# SERDES_10G0 register map
Vendor: Texas Instruments
Peripheral module from a debugger description file (folder J7VCL).
Registers are 32-bit, access per field, reset 0x0 unless marked. A register's access mark holds for its fields unless they carry their own. Offsets are as the file gives them; lines under a group give offsets from that group; [hi:lo] are bit positions; {n}, {i} and the like mark numbered series; 'fields as' and 'values as' point back to an identical list; <NAME> marks a mode.

## SERDES_10G0 (part 1 of 8)
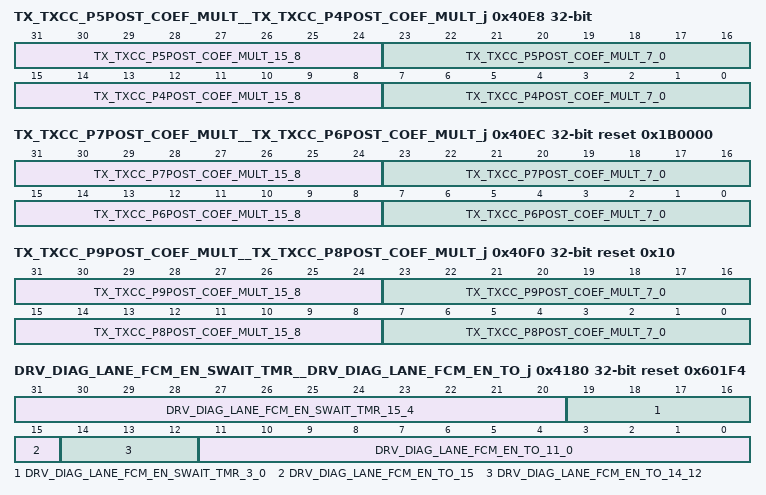
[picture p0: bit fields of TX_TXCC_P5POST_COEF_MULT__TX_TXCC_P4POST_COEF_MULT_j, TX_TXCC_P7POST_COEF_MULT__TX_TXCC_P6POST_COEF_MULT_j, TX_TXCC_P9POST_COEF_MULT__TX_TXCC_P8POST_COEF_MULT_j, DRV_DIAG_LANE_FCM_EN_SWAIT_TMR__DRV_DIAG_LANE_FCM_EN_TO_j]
0x40E8 TX_TXCC_P5POST_COEF_MULT__TX_TXCC_P4POST_COEF_MULT_j — Preset 4 post emphasis coefficient multiplier value register Offset = 40E8h + (j * 400h); where j = 0h to 3h
  [31:24] TX_TXCC_P5POST_COEF_MULT_15_8 ro — Reserved
  [23:16] TX_TXCC_P5POST_COEF_MULT_7_0 rw — Preset 5 post emphasis coefficient multiplier value : The value in this field specifies the multiplier value used to generate the preset 5 post emphasis coefficient value from the FS value.
  [15:8] TX_TXCC_P4POST_COEF_MULT_15_8 ro — Reserved
  [7:0] TX_TXCC_P4POST_COEF_MULT_7_0 rw — Preset 4 post emphasis coefficient multiplier value : The value in this field specifies the multiplier value used to generate the preset 4 post emphasis coefficient value from the FS value.
0x40EC TX_TXCC_P7POST_COEF_MULT__TX_TXCC_P6POST_COEF_MULT_j reset 0x1B0000 — Preset 6 post emphasis coefficient multiplier value register Offset = 40ECh + (j * 400h); where j = 0h to 3h
  [31:24] TX_TXCC_P7POST_COEF_MULT_15_8 ro — Reserved
  [23:16] TX_TXCC_P7POST_COEF_MULT_7_0 rw — Preset 7 post emphasis coefficient multiplier value : The value in this field specifies the multiplier value used to generate the preset 7 post emphasis coefficient value from the FS value.
  [15:8] TX_TXCC_P6POST_COEF_MULT_15_8 ro — Reserved
  [7:0] TX_TXCC_P6POST_COEF_MULT_7_0 rw — Preset 6 post emphasis coefficient multiplier value : The value in this field specifies the multiplier value used to generate the preset 6 post emphasis coefficient value from the FS value.
0x40F0 TX_TXCC_P9POST_COEF_MULT__TX_TXCC_P8POST_COEF_MULT_j reset 0x10 — Preset 8 post emphasis coefficient multiplier value register Offset = 40F0h + (j * 400h); where j = 0h to 3h
  [31:24] TX_TXCC_P9POST_COEF_MULT_15_8 ro — Reserved
  [23:16] TX_TXCC_P9POST_COEF_MULT_7_0 rw — Preset 9 post emphasis coefficient multiplier value : The value in this field specifies the multiplier value used to generate the preset 9 post emphasis coefficient value from the FS value.
  [15:8] TX_TXCC_P8POST_COEF_MULT_15_8 ro — Reserved
  [7:0] TX_TXCC_P8POST_COEF_MULT_7_0 rw — Preset 8 post emphasis coefficient multiplier value : The value in this field specifies the multiplier value used to generate the preset 8 post emphasis coefficient value from the FS value.
0x4180 DRV_DIAG_LANE_FCM_EN_SWAIT_TMR__DRV_DIAG_LANE_FCM_EN_TO_j reset 0x601F4 — Lane fast common mode enable timeout register Offset = 4180h + (j * 400h); where j = 0h to 3h
  [31:20] DRV_DIAG_LANE_FCM_EN_SWAIT_TMR_15_4 ro — Reserved
  [19:16] DRV_DIAG_LANE_FCM_EN_SWAIT_TMR_3_0 rw — Lane fast common mode enable sample wait timer value: This specifies the number of reference clock cycles the fast establishment of common mode process will wait between changing the state of the signals controlling the analog common mode sense circuits, and testing the results of the new state.
  [15] DRV_DIAG_LANE_FCM_EN_TO_15 rw — Bypass fast establishment of common mode enable: When enabled, the fast establishment of common mode function will be bypassed.
  [14:12] DRV_DIAG_LANE_FCM_EN_TO_14_12 ro — Reserved
  [11:0] DRV_DIAG_LANE_FCM_EN_TO_11_0 rw — Lane fast common mode enable timeout value: The usage of the value of this field is a function of the state of the bypass fast establishment of common mode enable bit in this register.
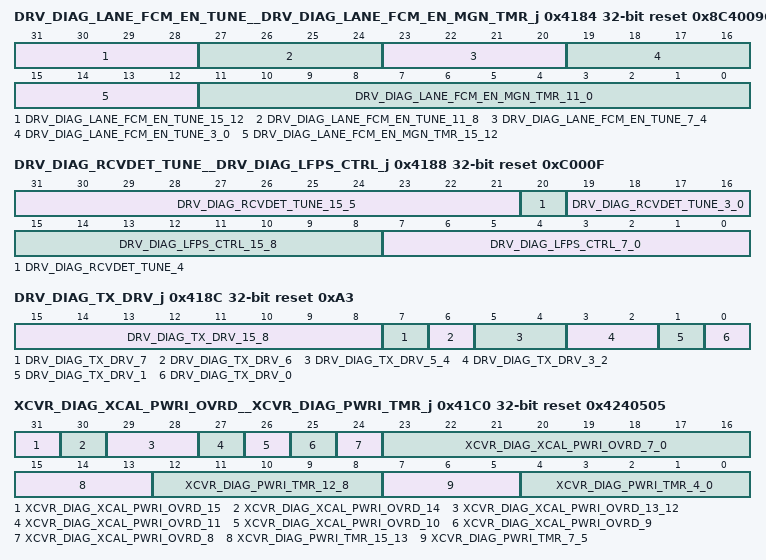
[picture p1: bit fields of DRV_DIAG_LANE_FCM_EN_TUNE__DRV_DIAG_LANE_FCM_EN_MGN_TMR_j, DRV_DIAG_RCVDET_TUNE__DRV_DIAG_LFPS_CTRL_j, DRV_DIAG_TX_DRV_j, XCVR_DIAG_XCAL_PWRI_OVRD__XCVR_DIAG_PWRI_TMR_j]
0x4184 DRV_DIAG_LANE_FCM_EN_TUNE__DRV_DIAG_LANE_FCM_EN_MGN_TMR_j reset 0x8C40096 — Lane fast common mode enable margin timer register Offset = 4184h + (j * 400h); where j = 0h to 3h
  [31:28] DRV_DIAG_LANE_FCM_EN_TUNE_15_12 ro — Reserved
  [27:24] DRV_DIAG_LANE_FCM_EN_TUNE_11_8 rw — Common mode sense reference DAC voltage initial test: This field sets the common mode detect reference voltage for the common mode detect comparator, when the fast establishment of common mode function is checking the initial state of the txda_cm_sense_comp_out signal.
  [23:20] DRV_DIAG_LANE_FCM_EN_TUNE_7_4 rw — Common mode sense reference DAC voltage high test: This field sets the common mode detect reference voltage for the common mode detect comparator, when the fast establishment of common mode function is waiting for the txda_cm_sense_comp_out signal from the analog to be driven high.
  [19:16] DRV_DIAG_LANE_FCM_EN_TUNE_3_0 rw — Common mode sense reference DAC voltage low test: This field sets the common mode detect reference voltage for the common mode detect comparator, when the fast establishment of common mode function is waiting for the txda_cm_sense_comp_out signal from the analog to be driven low.
  [15:12] DRV_DIAG_LANE_FCM_EN_MGN_TMR_15_12 ro — Reserved
  [11:0] DRV_DIAG_LANE_FCM_EN_MGN_TMR_11_0 rw — Lane fast common mode enable margin timer value: This specifies the number of reference clock cycles the fast establishment of common mode process will enable all the margin segments for.
0x4188 DRV_DIAG_RCVDET_TUNE__DRV_DIAG_LFPS_CTRL_j reset 0xC000F — Transmitter LFPS control register Offset = 4188h + (j * 400h); where j = 0h to 3h
  [31:21] DRV_DIAG_RCVDET_TUNE_15_5 ro — Reserved
  [20] DRV_DIAG_RCVDET_TUNE_4 rw — Receiver detect comparators output and or control: This bit controls how the receiver detect comparators are used to drive the txda_rcvdet_detected_n signal to the digital.
  [19:16] DRV_DIAG_RCVDET_TUNE_3_0 rw — Receiver detect reference DAC voltage: This field sets the receiver detect reference voltage for the receiver detect comparator.
  [15:8] DRV_DIAG_LFPS_CTRL_15_8 ro — Reserved
  [7:0] DRV_DIAG_LFPS_CTRL_7_0 rw — LFPS half period clocks: Specifies the number of clock cycles required to implement one half of a LFPS period, by the transmitter LFPS controller.
0x418C DRV_DIAG_TX_DRV_j reset 0xA3 — TX driver diagnostic register Offset = 418Ch + (j * 400h); where j = 0h to 3h
  [15:8] DRV_DIAG_TX_DRV_15_8 ro — Reserved
  [7] DRV_DIAG_TX_DRV_7 rw — TX boost enable: Increases the transmitter amplitude for fast data transitions, by controlling the txda_drv_boost_en signal going to the analog.
  [6] DRV_DIAG_TX_DRV_6 ro — Reserved
  [5:4] DRV_DIAG_TX_DRV_5_4 rw — TX boost tune: Controls the transmitter boost amplitude when the transmitter boost function is enabled using the TX boost enable bit in this register, by controlling the txda_drv_boost_tune signal going to the analog.
  [3:2] DRV_DIAG_TX_DRV_3_2 ro — Reserved
  [1] DRV_DIAG_TX_DRV_1 rw — TX pre-driver pull up control: When the pre-driver is disabled, this bit controls the state of the pre-driver output, by controlling the txda_drv_predrv_pullup signal going to the analog.
  [0] DRV_DIAG_TX_DRV_0 rw — TX driver margin type: Selects the margining type the driver will operate in, by controlling the txda_drv_margin_type signal going to the analog.
0x41C0 XCVR_DIAG_XCAL_PWRI_OVRD__XCVR_DIAG_PWRI_TMR_j reset 0x4240505 — Transceiver power island control timer register Offset = 41C0h + (j * 400h); where j = 0h to 3h
  [31] XCVR_DIAG_XCAL_PWRI_OVRD_15 rw — Power island controller input override enable: When enabled, the power island control state machine input override bits in this register will drive the power island control state machine directly, and override any control from other state machines in the macro.
  [30] XCVR_DIAG_XCAL_PWRI_OVRD_14 rw — Power island controller output override enable: When enabled, the power island control state machine output override bits in this register will drive the power island control state machine outputs, and override any control from power island control state machine.
  [29:28] XCVR_DIAG_XCAL_PWRI_OVRD_13_12 ro — Reserved
  [27] XCVR_DIAG_XCAL_PWRI_OVRD_11 rw — Power suspend request override: When enabled, this bit will override the power_suspend_req input of the power island control state machine.
  [26] XCVR_DIAG_XCAL_PWRI_OVRD_10 ro — Power suspend acknowledge: This is the current state of the power_suspend_ack output from the power island control state machine.
  [25] XCVR_DIAG_XCAL_PWRI_OVRD_9 rw — Power recover request override: When enabled, this bit will override the power_recover_req input of the power island control state machine.
  [24] XCVR_DIAG_XCAL_PWRI_OVRD_8 ro — Power recover acknowledge: This is the current state of the power_recover_ack output from the power island control state machine.
  [23:16] XCVR_DIAG_XCAL_PWRI_OVRD_7_0 rw — Power island controller output override: When enabled, the bits in this field will override the output signals from the power island control state machine.
  [15:13] XCVR_DIAG_PWRI_TMR_15_13 ro — Reserved
  [12:8] XCVR_DIAG_PWRI_TMR_12_8 rw — Power enable phase 2 timer value: This specifies the number of PSM clock cycles the power island control state machines in the transceiver will wait in the power phase 2 enable states, in order to allow enough time for the second phase of the switched domain to power up, before deactivating the isolation functions.
  [7:5] XCVR_DIAG_PWRI_TMR_7_5 ro — Reserved
  [4:0] XCVR_DIAG_PWRI_TMR_4_0 rw — Power enable phase 1 timer value: This specifies the number of PSM clock cycles the power island control state machines in the transceiver will wait in the power phase 1 enable states, in order to allow enough time for the first phase of the switched domain to power up, before enabling the second phase of the power up.
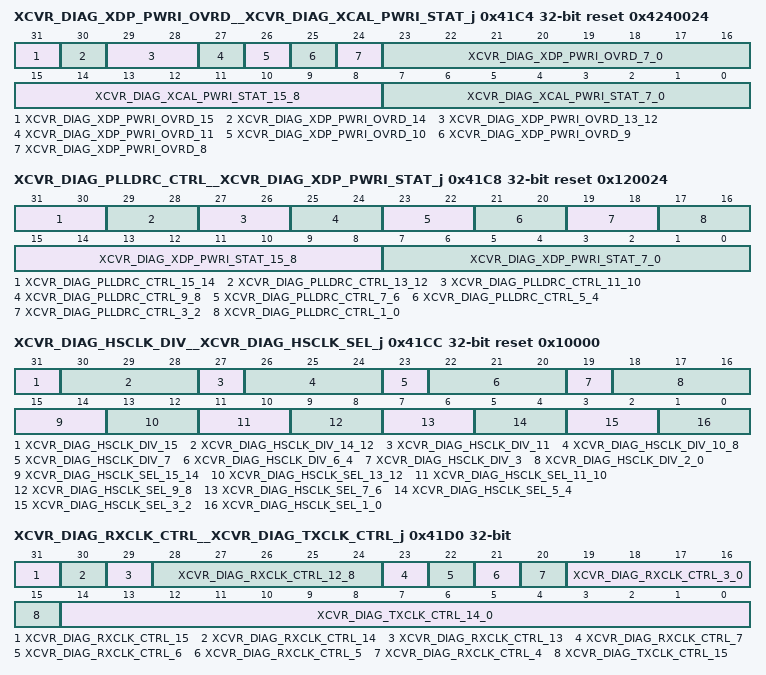
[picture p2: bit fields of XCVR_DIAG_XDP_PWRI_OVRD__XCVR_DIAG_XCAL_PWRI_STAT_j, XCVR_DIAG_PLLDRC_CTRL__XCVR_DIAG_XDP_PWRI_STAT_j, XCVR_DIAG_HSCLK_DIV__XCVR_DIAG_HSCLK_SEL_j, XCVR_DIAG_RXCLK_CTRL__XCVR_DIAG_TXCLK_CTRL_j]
0x41C4 XCVR_DIAG_XDP_PWRI_OVRD__XCVR_DIAG_XCAL_PWRI_STAT_j reset 0x4240024 — Transceiver transceiver calibration power island control status register Offset = 41C4h + (j * 400h); where j = 0h to 3h
  [31] XCVR_DIAG_XDP_PWRI_OVRD_15 rw — Power island controller input override enable: When enabled, the power island control state machine input override bits in this register will drive the power island control state machine directly, and override any control from other state machines in the macro.
  [30] XCVR_DIAG_XDP_PWRI_OVRD_14 rw — Power island controller output override enable: When enabled, the power island control state machine output override bits in this register will drive the power island control state machine outputs, and override any control from power island control state machine.
  [29:28] XCVR_DIAG_XDP_PWRI_OVRD_13_12 ro — Reserved
  [27] XCVR_DIAG_XDP_PWRI_OVRD_11 rw — Power suspend request override: When enabled, this bit will override the power_suspend_req input of the power island control state machine.
  [26] XCVR_DIAG_XDP_PWRI_OVRD_10 ro — Power suspend acknowledge: This is the current state of the power_suspend_ack output from the power island control state machine.
  [25] XCVR_DIAG_XDP_PWRI_OVRD_9 rw — Power recover request override: When enabled, this bit will override the power_recover_req input of the power island control state machine.
  [24] XCVR_DIAG_XDP_PWRI_OVRD_8 ro — Power recover acknowledge: This is the current state of the power_recover_ack output from the power island control state machine.
  [23:16] XCVR_DIAG_XDP_PWRI_OVRD_7_0 rw — Power island controller output override: When enabled, the bits in this field will override the output signals from the power island control state machine.
  [15:8] XCVR_DIAG_XCAL_PWRI_STAT_15_8 ro — Reserved
  [7:0] XCVR_DIAG_XCAL_PWRI_STAT_7_0 ro — Power island controller output status: This field indicates the current state of the output signals from the power island control state machine.
0x41C8 XCVR_DIAG_PLLDRC_CTRL__XCVR_DIAG_XDP_PWRI_STAT_j reset 0x120024 — Transceiver transceiver data path power island control status register Offset = 41C8h + (j * 400h); where j = 0h to 3h
  [31:30] XCVR_DIAG_PLLDRC_CTRL_15_14 rw — Digital PLL clock select standard mode 3: This bit controls which full rate PLL clock is selected, when xcvr_standard_mode is set to 2'b11.
  [29:28] XCVR_DIAG_PLLDRC_CTRL_13_12 rw — Digital PLL data rate divider standard mode 3 value: This field will directly control the xcvr_pll_clk_datart_div signal, which controls which divided clock is selected when generating the xcvr_pll_clk_datart clock, when xcvr_standard_mode is set to 2'b11.
  [27:26] XCVR_DIAG_PLLDRC_CTRL_11_10 rw — Digital PLL clock select standard mode 2: This bit controls which full rate PLL clock is selected, when xcvr_standard_mode is set to 2'b10.
  [25:24] XCVR_DIAG_PLLDRC_CTRL_9_8 rw — Digital PLL data rate divider standard mode 2 value: This field will directly control the xcvr_pll_clk_datart_div signal, which controls which divided clock is selected when generating the xcvr_pll_clk_datart clock, when xcvr_standard_mode is set to 2'b10.
  [23:22] XCVR_DIAG_PLLDRC_CTRL_7_6 rw — Digital PLL clock select standard mode 1: This bit controls which full rate PLL clock is selected, when xcvr_standard_mode is set to 2'b01.
  [21:20] XCVR_DIAG_PLLDRC_CTRL_5_4 rw — Digital PLL data rate divider standard mode 1 value: This field will directly control the xcvr_pll_clk_datart_div signal, which controls which divided clock is selected when generating the xcvr_pll_clk_datart clock, when xcvr_standard_mode is set to 2'b01.
  [19:18] XCVR_DIAG_PLLDRC_CTRL_3_2 rw — Digital PLL clock select standard mode 0: This bit controls which full rate PLL clock is selected, when xcvr_standard_mode is set to 2'b00.
  [17:16] XCVR_DIAG_PLLDRC_CTRL_1_0 rw — Digital PLL data rate divider standard mode 0 value: This field will directly control the xcvr_pll_clk_datart_div signal, which controls which divided clock is selected when generating the xcvr_pll_clk_datart clock, when xcvr_standard_mode is set to 2'b00.
  [15:8] XCVR_DIAG_XDP_PWRI_STAT_15_8 ro — Reserved
  [7:0] XCVR_DIAG_XDP_PWRI_STAT_7_0 ro — Power island controller output status: This field indicates the current state of the output signals from the power island control state machine.
0x41CC XCVR_DIAG_HSCLK_DIV__XCVR_DIAG_HSCLK_SEL_j reset 0x10000 — Transceiver high speed clock select register Offset = 41CCh + (j * 400h); where j = 0h to 3h
  [31] XCVR_DIAG_HSCLK_DIV_15 ro — Reserved
  [30:28] XCVR_DIAG_HSCLK_DIV_14_12 rw — Transceiver clock divider select standard mode 3: This field selects the divider value used to divide the selected analog high speed clock by when generating the transmit and receive clocks, when xcvr_standard_mode is set to 2'b11, by driving the xcvrda_xcvr_clk_div_sel signal to the analog, as specified below.
  [27] XCVR_DIAG_HSCLK_DIV_11 ro — Reserved
  [26:24] XCVR_DIAG_HSCLK_DIV_10_8 rw — Transceiver clock divider select standard mode 2: This field selects the divider value used to divide the selected analog high speed clock by when generating the transmit and receive clocks, when xcvr_standard_mode is set to 2'b10, by driving the xcvrda_xcvr_clk_div_sel signal to the analog, as specified below.
  [23] XCVR_DIAG_HSCLK_DIV_7 ro — Reserved
  [22:20] XCVR_DIAG_HSCLK_DIV_6_4 rw — Transceiver clock divider select standard mode 1: This field selects the divider value used to divide the selected analog high speed clock by when generating the transmit and receive clocks, when xcvr_standard_mode is set to 2'b01, by driving the xcvrda_xcvr_clk_div_sel signal to the analog, as specified below.
  [19] XCVR_DIAG_HSCLK_DIV_3 ro — Reserved
  [18:16] XCVR_DIAG_HSCLK_DIV_2_0 rw — Transceiver clock divider select standard mode 0: This field selects the divider value used to divide the selected analog high speed clock by when generating the transmit and receive clocks, when xcvr_standard_mode is set to 2'b00, by driving the xcvrda_xcvr_clk_div_sel signal to the analog, as specified below.
  [15:14] XCVR_DIAG_HSCLK_SEL_15_14 ro — Reserved
  [13:12] XCVR_DIAG_HSCLK_SEL_13_12 rw — High speed clock select standard mode 3: This specifies which analog high speed clock is selected when xcvr_standard_mode is set to 2'b11, by driving the xcvrda_clk_sel signal to the analog, as specified below.
  [11:10] XCVR_DIAG_HSCLK_SEL_11_10 ro — Reserved
  [9:8] XCVR_DIAG_HSCLK_SEL_9_8 rw — High speed clock select standard mode 2: This specifies which analog high speed clock is selected when xcvr_standard_mode is set to 2'b10, by driving the xcvrda_clk_sel signal to the analog, as specified below.
  [7:6] XCVR_DIAG_HSCLK_SEL_7_6 ro — Reserved
  [5:4] XCVR_DIAG_HSCLK_SEL_5_4 rw — High speed clock select standard mode 1: This specifies which analog high speed clock is selected when xcvr_standard_mode is set to 2'b01, by driving the xcvrda_clk_sel signal to the analog, as specified below.
  [3:2] XCVR_DIAG_HSCLK_SEL_3_2 ro — Reserved
  [1:0] XCVR_DIAG_HSCLK_SEL_1_0 rw — High speed clock select standard mode 0: This specifies which analog high speed clock is selected when xcvr_standard_mode is set to 2'b00, by driving the xcvrda_clk_sel signal to the analog, as specified below.
0x41D0 XCVR_DIAG_RXCLK_CTRL__XCVR_DIAG_TXCLK_CTRL_j — TX clock control register Offset = 41D0h + (j * 400h); where j = 0h to 3h
  [31] XCVR_DIAG_RXCLK_CTRL_15 rw — RX deserializer clock invert: This bit is used to optionally invert the deserializer clock (rxda_des_clk) for diagnostic purposes.
  [30] XCVR_DIAG_RXCLK_CTRL_14 rw — RX 2x clock enable: This bit enables the receiver 2x clock function, by driving the rxda_des_clk_2x_en signal going to the analog.
  [29] XCVR_DIAG_RXCLK_CTRL_13 rw — RX PI E path clock select: Controls which PI clock drives the E path clocks, by driving the rxda_pi_i_drv_e_en signal going to the analog.
  [28:24] XCVR_DIAG_RXCLK_CTRL_12_8 ro — Reserved
  [23] XCVR_DIAG_RXCLK_CTRL_7 rw — PI output clock divider enable standard mode 3: This bit controls the rxda_pi_out_clk_div_en to enable the PI output clock divider, when xcvr_standard_mode is set to 2'b11.
  [22] XCVR_DIAG_RXCLK_CTRL_6 rw — PI output clock divider enable standard mode 2: This bit controls the rxda_pi_out_clk_div_en to enable the PI output clock divider, when xcvr_standard_mode is set to 2'b10.
  [21] XCVR_DIAG_RXCLK_CTRL_5 rw — PI output clock divider enable standard mode 1: This bit controls the rxda_pi_out_clk_div_en to enable the PI output clock divider, when xcvr_standard_mode is set to 2'b01.
  [20] XCVR_DIAG_RXCLK_CTRL_4 rw — PI output clock divider enable standard mode 0: This bit controls the rxda_pi_out_clk_div_en to enable the PI output clock divider, when xcvr_standard_mode is set to 2'b00.
  [19:16] XCVR_DIAG_RXCLK_CTRL_3_0 ro — Reserved
  [15] XCVR_DIAG_TXCLK_CTRL_15 rw — TX serializer clock invert: This bit is used to optionally invert the serializer clock (txda_ser_clk) for diagnostic purposes.
  [14:0] XCVR_DIAG_TXCLK_CTRL_14_0 ro — Reserved
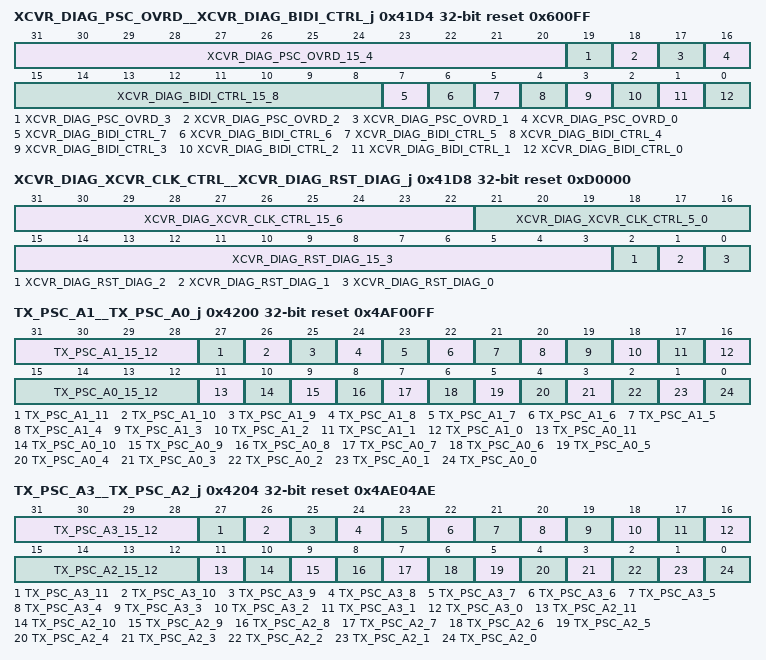
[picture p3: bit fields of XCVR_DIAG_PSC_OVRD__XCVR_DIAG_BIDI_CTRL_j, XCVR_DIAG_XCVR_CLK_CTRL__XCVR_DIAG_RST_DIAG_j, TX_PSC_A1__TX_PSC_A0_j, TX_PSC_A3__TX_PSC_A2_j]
0x41D4 XCVR_DIAG_PSC_OVRD__XCVR_DIAG_BIDI_CTRL_j reset 0x600FF — Transceiver bidirectional control register Offset = 41D4h + (j * 400h); where j = 0h to 3h
  [31:20] XCVR_DIAG_PSC_OVRD_15_4 ro — Reserved
  [19] XCVR_DIAG_PSC_OVRD_3 rw — Receiver DFE enable mask value standard mode 3: This bit will controls the rx_dfe_eq_enable_std_mask digital signal, which can be used to mask off the rxda_dfe_eq_enable signal coming from the power state controller and going into the analog, when xcvr_standard_mode is set to 2'b11.
  [18] XCVR_DIAG_PSC_OVRD_2 rw — Receiver DFE enable mask value standard mode 2: This bit will controls the rx_dfe_eq_enable_std_mask digital signal, which can be used to mask off the rxda_dfe_eq_enable signal coming from the power state controller and going into the analog, when xcvr_standard_mode is set to 2'b10.
  [17] XCVR_DIAG_PSC_OVRD_1 rw — Receiver DFE enable mask value standard mode 1: This bit will controls the rx_dfe_eq_enable_std_mask digital signal, which can be used to mask off the rxda_dfe_eq_enable signal coming from the power state controller and going into the analog, when xcvr_standard_mode is set to 2'b01.
  [16] XCVR_DIAG_PSC_OVRD_0 rw — Receiver DFE enable mask value standard mode 0: This bit will controls the rx_dfe_eq_enable_std_mask digital signal, which can be used to mask off the rxda_dfe_eq_enable signal coming from the power state controller and going into the analog, when xcvr_standard_mode is set to 2'b00.
  [15:8] XCVR_DIAG_BIDI_CTRL_15_8 ro — Reserved
  [7] XCVR_DIAG_BIDI_CTRL_7 rw — Receiver enable standard mode 3: When bidirectional bumps are implemented in the transceiver, this bit is a global enable for the receiver function, when xcvr_standard_mode is set to 2'b11.
  [6] XCVR_DIAG_BIDI_CTRL_6 rw — Receiver enable standard mode 2: When bidirectional bumps are implemented in the transceiver, this bit is a global enable for the receiver function, when xcvr_standard_mode is set to 2'b10.
  [5] XCVR_DIAG_BIDI_CTRL_5 rw — Receiver enable standard mode 1: When bidirectional bumps are implemented in the transceiver, this bit is a global enable for the receiver function, when xcvr_standard_mode is set to 2'b01.
  [4] XCVR_DIAG_BIDI_CTRL_4 rw — Receiver enable standard mode 0: When bidirectional bumps are implemented in the transceiver, this bit is a global enable for the receiver function, when xcvr_standard_mode is set to 2'b00.
  [3] XCVR_DIAG_BIDI_CTRL_3 rw — Transmitter enable standard mode 3: When bidirectional bumps are implemented in the transceiver, this bit is a global enable for the transmitter function, when xcvr_standard_mode is set to 2'b11.
  [2] XCVR_DIAG_BIDI_CTRL_2 rw — Transmitter enable standard mode 2: When bidirectional bumps are implemented in the transceiver, this bit is a global enable for the transmitter function, when xcvr_standard_mode is set to 2'b10.
  [1] XCVR_DIAG_BIDI_CTRL_1 rw — Transmitter enable standard mode 1: When bidirectional bumps are implemented in the transceiver, this bit is a global enable for the transmitter function, when xcvr_standard_mode is set to 2'b01.
  [0] XCVR_DIAG_BIDI_CTRL_0 rw — Transmitter enable standard mode 0: When bidirectional bumps are implemented in the transceiver, this bit is a global enable for the transmitter function, when xcvr_standard_mode is set to 2'b00.
0x41D8 XCVR_DIAG_XCVR_CLK_CTRL__XCVR_DIAG_RST_DIAG_j reset 0xD0000 — Transceiver control reset diagnostic register Offset = 41D8h + (j * 400h); where j = 0h to 3h
  [31:22] XCVR_DIAG_XCVR_CLK_CTRL_15_6 ro — Reserved
  [21:16] XCVR_DIAG_XCVR_CLK_CTRL_5_0 rw — Transceiver clock enable delay timer value: This specifies the number of xcvr_psm_clk clock cycles that the transceiver high speed clock reset release state machine will wait between when it drives the analog transceiver clock enable signal active, and when it will initiate the process to release the reset for this clock.
  [15:3] XCVR_DIAG_RST_DIAG_15_3 ro — Reserved
  [2] XCVR_DIAG_RST_DIAG_2 ro — Current state of the tx_coef_calc_reset_n reset.
  [1] XCVR_DIAG_RST_DIAG_1 ro — Current state of the xcvr_psm_reset_n reset.
  [0] XCVR_DIAG_RST_DIAG_0 ro — Current state of the xcvr_ref_clk_reset_n reset.
0x41DC XCVR_DIAG_DCYA_j rw — Transceiver digital cover your alternatives register Offset = 41DCh + (j * 400h); where j = 0h to 3h
  [31:16] XCVR_DIAG_DCYA_15_0 — Reserved - spare
0x4200 TX_PSC_A1__TX_PSC_A0_j reset 0x4AF00FF — Transmitter A0 power state definition register Offset = 4200h + (j * 400h); where j = 0h to 3h
  [31:28] TX_PSC_A1_15_12 ro — Reserved
  [27] TX_PSC_A1_11 rw — TX driver common mode enable extend control
  [26] TX_PSC_A1_10 rw — Force txda_lfps_sel active
  [25] TX_PSC_A1_9 rw — LFPS clock gate enable
  [24] TX_PSC_A1_8 rw — Reserved - spare
  [23] TX_PSC_A1_7 rw — Transmitter low current mode
  [22] TX_PSC_A1_6 rw — Transmitter mission mode enable
  [21] TX_PSC_A1_5 rw — TX driver common mode enable
  [20] TX_PSC_A1_4 rw — TX driver enable
  [19] TX_PSC_A1_3 rw — TX post-emphasis enable (C+1)
  [18] TX_PSC_A1_2 rw — TX pre-emphasis enable (C-1)
  [17] TX_PSC_A1_1 rw — TX pre-driver enable
  [16] TX_PSC_A1_0 rw — TX serializer enable
  [15:12] TX_PSC_A0_15_12 ro — Reserved
  [11] TX_PSC_A0_11 rw — TX driver common mode enable extend control: Specifies which power states the tx_cmn_mode_en_ext signal is considered valid in and can be used to force the driver to continue to be in the common mode state.
  [10] TX_PSC_A0_10 rw — Force txda_lfps_sel active: Setting this bit forces the txda_lfps_sel signal going to the analog to be driven active.
  [9] TX_PSC_A0_9 rw — LFPS clock gate enable: Enables the LFPS clock gate when an LFPS clock is required.
  [8] TX_PSC_A0_8 rw — Reserved - spare
  [7] TX_PSC_A0_7 rw — Transmitter low current mode: Enables a low current consumption mode within the common mode voltage circuit in the driver, via the txda_drv_idle_lowi_en signal going to the analog.
  [6] TX_PSC_A0_6 rw — Transmitter mission mode enable: Enables the analog circuits in the driver required to run in mission mode, via the txda_drv_mission_en signal going to the analog.
  [5] TX_PSC_A0_5 rw — TX driver common mode enable: Enables the common mode voltage circuits in the driver.
  [4] TX_PSC_A0_4 rw — TX driver enable: Enables the transmitter driver, via the H bridge driver controller.
  [3] TX_PSC_A0_3 rw — TX post-emphasis enable (C+1): Enables the transmitter circuits related to the post-emphasis function.
  [2] TX_PSC_A0_2 rw — TX pre-emphasis enable (C-1): Enables the transmitter circuits related to the pre-emphasis function.
  [1] TX_PSC_A0_1 rw — TX pre-driver enable: Enables the transmitter pre-driver, driver data selection MUX, and receiver detect.
  [0] TX_PSC_A0_0 rw — TX serializer enable: Enables the serializer and related clock divider circuits.
0x4204 TX_PSC_A3__TX_PSC_A2_j reset 0x4AE04AE — Transmitter A2 power state definition register Offset = 4204h + (j * 400h); where j = 0h to 3h
  [31:28] TX_PSC_A3_15_12 ro — Reserved
  [27] TX_PSC_A3_11 rw — TX driver common mode enable extend control
  [26] TX_PSC_A3_10 rw — Force txda_lfps_sel active
  [25] TX_PSC_A3_9 rw — LFPS clock gate enable
  [24] TX_PSC_A3_8 rw — Reserved - spare
  [23] TX_PSC_A3_7 rw — Transmitter low current mode
  [22] TX_PSC_A3_6 rw — Transmitter mission mode enable
  [21] TX_PSC_A3_5 rw — TX driver common mode enable
  [20] TX_PSC_A3_4 rw — TX driver enable
  [19] TX_PSC_A3_3 rw — TX post-emphasis enable (C+1)
  [18] TX_PSC_A3_2 rw — TX pre-emphasis enable (C-1)
  [17] TX_PSC_A3_1 rw — TX pre-driver enable
  [16] TX_PSC_A3_0 rw — TX serializer enable
  [15:12] TX_PSC_A2_15_12 ro — Reserved
  [11] TX_PSC_A2_11 rw — TX driver common mode enable extend control
  [10] TX_PSC_A2_10 rw — Force txda_lfps_sel active
  [9] TX_PSC_A2_9 rw — LFPS clock gate enable
  [8] TX_PSC_A2_8 rw — Reserved - spare
  [7] TX_PSC_A2_7 rw — Transmitter low current mode
  [6] TX_PSC_A2_6 rw — Transmitter mission mode enable
  [5] TX_PSC_A2_5 rw — TX driver common mode enable
  [4] TX_PSC_A2_4 rw — TX driver enable
  [3] TX_PSC_A2_3 rw — TX post-emphasis enable (C+1)
  [2] TX_PSC_A2_2 rw — TX pre-emphasis enable (C-1)
  [1] TX_PSC_A2_1 rw — TX pre-driver enable
  [0] TX_PSC_A2_0 rw — TX serializer enable
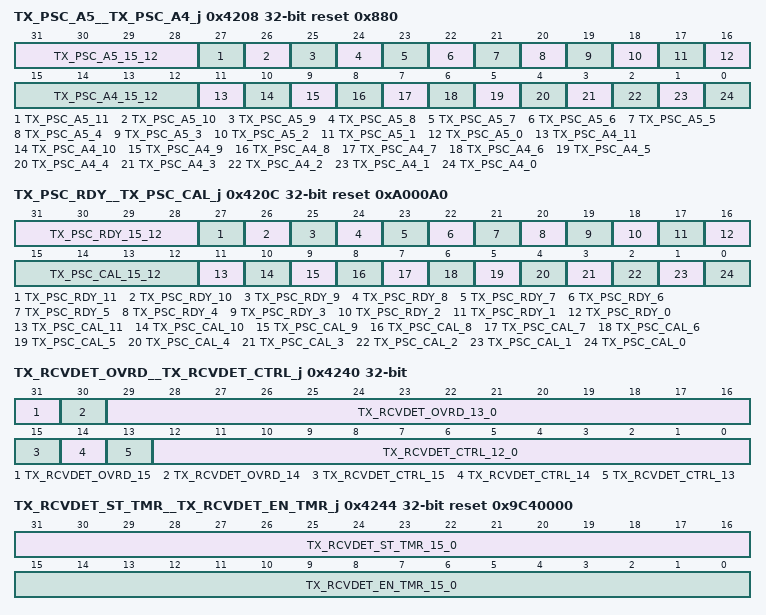
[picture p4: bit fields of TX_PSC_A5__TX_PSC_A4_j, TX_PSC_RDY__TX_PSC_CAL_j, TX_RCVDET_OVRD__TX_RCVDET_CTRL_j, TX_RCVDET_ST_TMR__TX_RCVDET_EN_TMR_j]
0x4208 TX_PSC_A5__TX_PSC_A4_j reset 0x880 — Transmitter A4 power state definition register Offset = 4208h + (j * 400h); where j = 0h to 3h
  [31:28] TX_PSC_A5_15_12 ro — Reserved
  [27] TX_PSC_A5_11 rw — TX driver common mode enable extend control
  [26] TX_PSC_A5_10 rw — Force txda_lfps_sel active
  [25] TX_PSC_A5_9 rw — LFPS clock gate enable
  [24] TX_PSC_A5_8 rw — Reserved - spare
  [23] TX_PSC_A5_7 rw — Transmitter low current mode
  [22] TX_PSC_A5_6 rw — Transmitter mission mode enable
  [21] TX_PSC_A5_5 rw — TX driver common mode enable
  [20] TX_PSC_A5_4 rw — TX driver enable
  [19] TX_PSC_A5_3 rw — TX post-emphasis enable (C+1)
  [18] TX_PSC_A5_2 rw — TX pre-emphasis enable (C-1)
  [17] TX_PSC_A5_1 rw — TX pre-driver enable
  [16] TX_PSC_A5_0 rw — TX serializer enable
  [15:12] TX_PSC_A4_15_12 ro — Reserved
  [11] TX_PSC_A4_11 rw — TX driver common mode enable extend control
  [10] TX_PSC_A4_10 rw — Force txda_lfps_sel active
  [9] TX_PSC_A4_9 rw — LFPS clock gate enable
  [8] TX_PSC_A4_8 rw — Reserved - spare
  [7] TX_PSC_A4_7 rw — Transmitter low current mode
  [6] TX_PSC_A4_6 rw — Transmitter mission mode enable
  [5] TX_PSC_A4_5 rw — TX driver common mode enable
  [4] TX_PSC_A4_4 rw — TX driver enable
  [3] TX_PSC_A4_3 rw — TX post-emphasis enable (C+1)
  [2] TX_PSC_A4_2 rw — TX pre-emphasis enable (C-1)
  [1] TX_PSC_A4_1 rw — TX pre-driver enable
  [0] TX_PSC_A4_0 rw — TX serializer enable
0x420C TX_PSC_RDY__TX_PSC_CAL_j reset 0xA000A0 — Transmitter calibration power state definition register Offset = 420Ch + (j * 400h); where j = 0h to 3h
  [31:28] TX_PSC_RDY_15_12 ro — Reserved
  [27] TX_PSC_RDY_11 rw — TX driver common mode enable extend control
  [26] TX_PSC_RDY_10 rw — Force txda_lfps_sel active
  [25] TX_PSC_RDY_9 rw — LFPS clock gate enable
  [24] TX_PSC_RDY_8 rw — Reserved - spare
  [23] TX_PSC_RDY_7 rw — Transmitter low current mode
  [22] TX_PSC_RDY_6 rw — Transmitter mission mode enable
  [21] TX_PSC_RDY_5 rw — TX driver common mode enable
  [20] TX_PSC_RDY_4 rw — TX driver enable
  [19] TX_PSC_RDY_3 rw — TX post-emphasis enable (C+1)
  [18] TX_PSC_RDY_2 rw — TX pre-emphasis enable (C-1)
  [17] TX_PSC_RDY_1 rw — TX pre-driver enable
  [16] TX_PSC_RDY_0 rw — TX serializer enable
  [15:12] TX_PSC_CAL_15_12 ro — Reserved
  [11] TX_PSC_CAL_11 rw — TX driver common mode enable extend control
  [10] TX_PSC_CAL_10 rw — Force txda_lfps_sel active
  [9] TX_PSC_CAL_9 rw — LFPS clock gate enable
  [8] TX_PSC_CAL_8 rw — Reserved - spare
  [7] TX_PSC_CAL_7 rw — Transmitter low current mode
  [6] TX_PSC_CAL_6 rw — Transmitter mission mode enable
  [5] TX_PSC_CAL_5 rw — TX driver common mode enable
  [4] TX_PSC_CAL_4 rw — TX driver enable
  [3] TX_PSC_CAL_3 rw — TX post-emphasis enable (C+1)
  [2] TX_PSC_CAL_2 rw — TX pre-emphasis enable (C-1)
  [1] TX_PSC_CAL_1 rw — TX pre-driver enable
  [0] TX_PSC_CAL_0 rw — TX serializer enable
0x4240 TX_RCVDET_OVRD__TX_RCVDET_CTRL_j — Transmit receiver detect control register Offset = 4240h + (j * 400h); where j = 0h to 3h
  [31] TX_RCVDET_OVRD_15 rw — Receiver detect override enable: Activation (1'b1) of this register bit enables the tx_rcv_detected output from the receiver detect state machine to be driven directly by the receiver detect override bit in this register.
  [30] TX_RCVDET_OVRD_14 rw — Receiver detect override: When the receiver detect override enable bit in this register is active (1'b1), this bit will directly control the tx_rcv_detected output from the receiver detect state machine.
  [29:16] TX_RCVDET_OVRD_13_0 ro — Reserved
  [15] TX_RCVDET_CTRL_15 rw — Start receiver detect: Activating (1'b1) this bit will start the receiver detect process.
  [14] TX_RCVDET_CTRL_14 ro — Receiver detect process done: This bit will be set to 1'b1 when the receiver detect process is complete.
  [13] TX_RCVDET_CTRL_13 ro — Receiver detected: When the receiver detect process is complete, this register bit will indicate the current state of the tx_rcv_detected pin.
  [12:0] TX_RCVDET_CTRL_12_0 ro — Reserved
0x4244 TX_RCVDET_ST_TMR__TX_RCVDET_EN_TMR_j rw reset 0x9C40000 — Transmit receiver detect enable timer register Offset = 4244h + (j * 400h); where j = 0h to 3h
  [31:16] TX_RCVDET_ST_TMR_15_0 — Start wait time value: This is the number of clocks the receiver detect state machine waits between driving the txda_rcvdet_start signal active and checking the results on the txda_rcvdet_detected_n signal coming from the analog.
  [15:0] TX_RCVDET_EN_TMR_15_0 — Enable wait time value: This is the number of clocks the receiver detect state machine waits between driving the txda_rcvdet_en signal active and driving the txda_rcvdet_start signal active going to the analog.
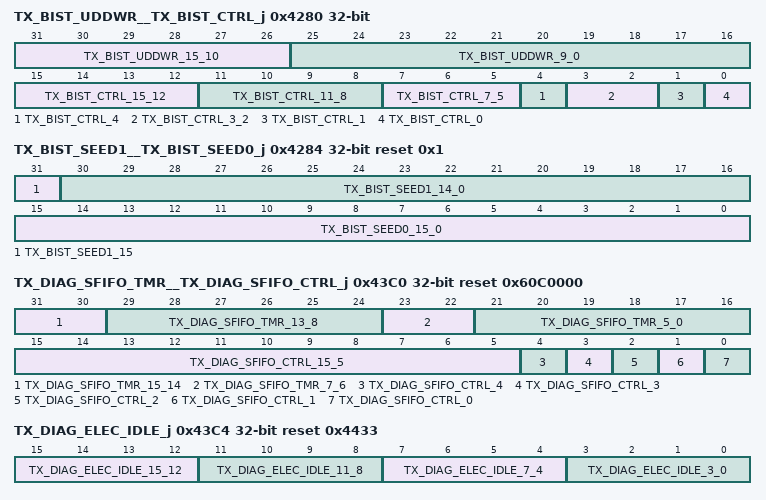
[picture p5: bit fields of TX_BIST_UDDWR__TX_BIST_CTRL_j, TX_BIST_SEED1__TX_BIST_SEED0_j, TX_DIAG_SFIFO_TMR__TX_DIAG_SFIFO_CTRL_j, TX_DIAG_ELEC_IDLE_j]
0x4280 TX_BIST_UDDWR__TX_BIST_CTRL_j — Transmit BIST control register Offset = 4280h + (j * 400h); where j = 0h to 3h
  [31:26] TX_BIST_UDDWR_15_10 ro — Reserved
  [25:16] TX_BIST_UDDWR_9_0 wo — Transmitter BIST user defined data: Writing a data word to this field will result in that data word being placed in the next available position in the transmitter BIST user defined data FIFO.
  [15:12] TX_BIST_CTRL_15_12 ro — Reserved
  [11:8] TX_BIST_CTRL_11_8 rw — Transmitter BIST mode: Controls which mode the BIST will operate in.
  [7:5] TX_BIST_CTRL_7_5 ro — Reserved
  [4] TX_BIST_CTRL_4 rw — Transmitter BIST force error: When this bit transitions from 1'b0 to 1'b1, the transmit BIST controller will force an error to be transmitted from the BIST logic, by inverting one of the parallel data bits.
  [3:2] TX_BIST_CTRL_3_2 ro — Reserved
  [1] TX_BIST_CTRL_1 wo — Transmitter BIST user defined data FIFO clear: Writing a 1'b1 to this bit will clear the transmitter BIST user defined data FIFO.
  [0] TX_BIST_CTRL_0 rw — Transmitter BIST enable: This bit enables the transmitter BIST function.
0x4284 TX_BIST_SEED1__TX_BIST_SEED0_j reset 0x1 — Transmit BIST PRBS seed 0 register Offset = 4284h + (j * 400h); where j = 0h to 3h
  [31] TX_BIST_SEED1_15 ro — Reserved
  [30:16] TX_BIST_SEED1_14_0 rw — Transmitter BIST PRBS seed (30:16): When the BIST is in PRBS mode, this field provides a seed for the PRBS, such that different lanes can have different BIST patterns.
  [15:0] TX_BIST_SEED0_15_0 rw — Transmitter BIST PRBS seed (15:0): When the BIST is in PRBS mode, this field provides a seed for the PRBS, such that different lanes can have different BIST patterns.
0x43C0 TX_DIAG_SFIFO_TMR__TX_DIAG_SFIFO_CTRL_j reset 0x60C0000 — TX sync FIFO diagnostic control register Offset = 43C0h + (j * 400h); where j = 0h to 3h
  [31:30] TX_DIAG_SFIFO_TMR_15_14 ro — Reserved
  [29:24] TX_DIAG_SFIFO_TMR_13_8 rw — FIFO alignment settle delay: This field specifies the number of clocks to wait for a prior change to the enqueue pointer to complete before initiating the check phase of the alignment procedure in the sync FIFO.
  [23:22] TX_DIAG_SFIFO_TMR_7_6 ro — Reserved
  [21:16] TX_DIAG_SFIFO_TMR_5_0 rw — FIFO alignment detect delay: This field specifies the number of clocks to wait in the delay state for each phase of the alignment procedure in the sync FIFO.
  [15:5] TX_DIAG_SFIFO_CTRL_15_5 ro — Reserved
  [4] TX_DIAG_SFIFO_CTRL_4 rw — FIFO enqueue pointer bump: This bit can be used to decrement the enqueue pointer relative to the dequeue pointer, for diagnostic purposes.
  [3] TX_DIAG_SFIFO_CTRL_3 ro — FIFO pointers overlapping: This bit indicates that the current enqueue and dequeue pointers have been detected as overlapping.
  [2] TX_DIAG_SFIFO_CTRL_2 ro — FIFO alignment acknowledge: This bit indicates that the FIFO alignment process is complete, as initiated either automatically by the hardware of the FIFO alignment enable override bits in this register.
  [1] TX_DIAG_SFIFO_CTRL_1 rw — FIFO alignment enable override enable: This bit enables the FIFO alignment enable override register to drive the fifo_align_en pin of the FIFO directly for diagnostic purposes.
  [0] TX_DIAG_SFIFO_CTRL_0 rw — FIFO alignment enable override: When enabled by the FIFO alignment enable override enable bit in this register, this bit directly controls the fifo_align_en pin of the FIFO to provide a means of running the FIFO alignment function for diagnostic purposes.
0x43C4 TX_DIAG_ELEC_IDLE_j rw reset 0x4433 — TX electrical idle diagnostic register Offset = 43C4h + (j * 400h); where j = 0h to 3h
  [15:12] TX_DIAG_ELEC_IDLE_15_12 — TX electrical idle exit delay 16 bit data width : This field controls the amount of additional delay added to the electrical idle signal after the sync FIFO, when exiting the electrical idle state for 16 bit data width modes.
  [11:8] TX_DIAG_ELEC_IDLE_11_8 — TX electrical idle entry delay 16 bit data width : This field controls the amount of additional delay added to the electrical idle signal after the sync FIFO, when entering the electrical idle state for 16 bit data width modes.
  [7:4] TX_DIAG_ELEC_IDLE_7_4 — TX electrical idle exit delay 20 bit data width : This field controls the amount of additional delay added to the electrical idle signal after the sync FIFO, when exiting the electrical idle state for 20 bit data width modes.
  [3:0] TX_DIAG_ELEC_IDLE_3_0 — TX electrical idle entry delay 20 bit data width : This field controls the amount of additional delay added to the electrical idle signal after the sync FIFO, when entering the electrical idle state for 20 bit data width modes.
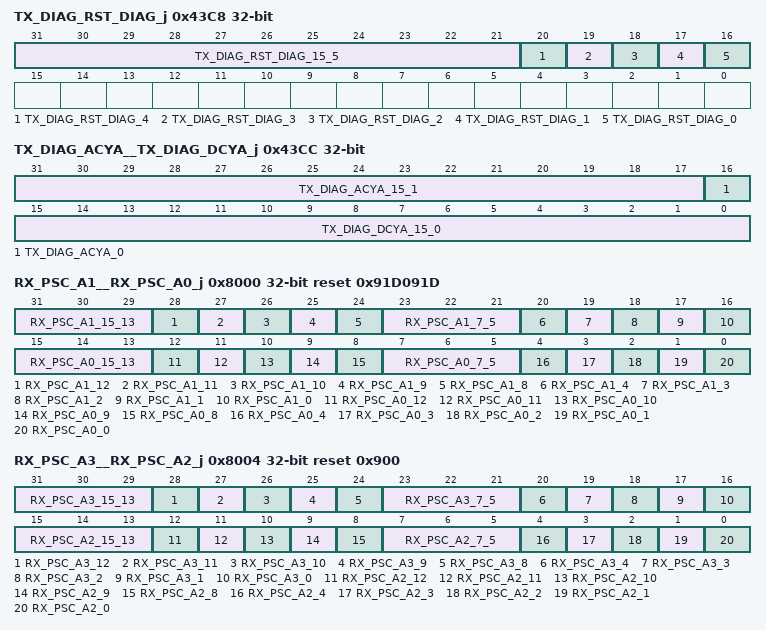
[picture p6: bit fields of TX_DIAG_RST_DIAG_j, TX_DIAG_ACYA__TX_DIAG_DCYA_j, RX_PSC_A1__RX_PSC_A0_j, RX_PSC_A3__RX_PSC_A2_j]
0x43C8 TX_DIAG_RST_DIAG_j ro — Transmitter control reset diagnostic register Offset = 43C8h + (j * 400h); where j = 0h to 3h
  [31:21] TX_DIAG_RST_DIAG_15_5 — Reserved
  [20] TX_DIAG_RST_DIAG_4 — Current state of the txda_tx_clk_reset_n reset.
  [19] TX_DIAG_RST_DIAG_3 — Current state of the tx_dig_reset_n reset.
  [18] TX_DIAG_RST_DIAG_2 — Current state of the tx_sync_fifo_deq_rst_n reset.
  [17] TX_DIAG_RST_DIAG_1 — Current state of the tx_sync_fifo_enq_rst_n reset.
  [16] TX_DIAG_RST_DIAG_0 — Current state of the tx_lfps_reset_n reset.
0x43CC TX_DIAG_ACYA__TX_DIAG_DCYA_j rw — Transmitter digital cover your alternatives register Offset = 43CCh + (j * 400h); where j = 0h to 3h
  [31:17] TX_DIAG_ACYA_15_1 — Reserved - spare
  [16] TX_DIAG_ACYA_0 — HBDC latch control: Controls the state of the latches associated with the H bridge driver controller related signals in the H bridge driver encoder logic digital in the transmitter analog, as well as the boost enable and level control signals.
  [15:0] TX_DIAG_DCYA_15_0 — Reserved - spare
0x8000 RX_PSC_A1__RX_PSC_A0_j reset 0x91D091D — Receiver A0 power state definition register Offset = 8000h + (j * 400h); where j = 0h to 3h
  [31:29] RX_PSC_A1_15_13 ro — Reserved
  [28] RX_PSC_A1_12 rw — RX signal detect enable extend control
  [27] RX_PSC_A1_11 rw — RX signal detect filter enable
  [26] RX_PSC_A1_10 rw — RX LFPS detect filter enable
  [25] RX_PSC_A1_9 rw — Reserved - spare
  [24] RX_PSC_A1_8 rw — RX signal detect enable
  [23:21] RX_PSC_A1_7_5 rw — Reserved - spare
  [20] RX_PSC_A1_4 rw — RX equalizer engine enable
  [19] RX_PSC_A1_3 rw — RX DFE equalization enable.
  [18] RX_PSC_A1_2 rw — RX PI enable
  [17] RX_PSC_A1_1 rw — RX e path enable (calibration and eye surf only)
  [16] RX_PSC_A1_0 rw — RX enable
  [15:13] RX_PSC_A0_15_13 ro — Reserved
  [12] RX_PSC_A0_12 rw — RX signal detect enable extend control: Specifies which power states the rx_sig_det_en_ext signal is considered valid in and can be used to force the signal detect functions to remain on.
  [11] RX_PSC_A0_11 rw — RX signal detect filter enable: Enables the receiver signal detect filter function in the digital receiver controller.
  [10] RX_PSC_A0_10 rw — RX LFPS detect filter enable: Enables the receiver LFPS detect filter function in the digital receiver controller.
  [9] RX_PSC_A0_9 rw — Reserved - spare
  [8] RX_PSC_A0_8 rw — RX signal detect enable: Enables the receiver signal detect function.
  [7:5] RX_PSC_A0_7_5 rw — Reserved - spare
  [4] RX_PSC_A0_4 rw — RX equalizer engine enable: Specifies which power state the REE runs in.
  [3] RX_PSC_A0_3 rw — RX DFE equalization enable: Enables the receiver DFE equalization circuits, via the rxda_dfe_eq_enable signal.
  [2] RX_PSC_A0_2 rw — RX PI enable: Enables the receiver circuits related to the PI and associated clocking components.
  [1] RX_PSC_A0_1 rw — RX e path enable (calibration and eye surf only) : Enables the receiver circuits related to the eye plot PI and e path deserializer for calibration and eye surf.
  [0] RX_PSC_A0_0 rw — RX enable: Enables the receiver circuits related to the CDRLF, Sampler, FE, and Deserializer.
0x8004 RX_PSC_A3__RX_PSC_A2_j reset 0x900 — Receiver A2 power state definition register Offset = 8004h + (j * 400h); where j = 0h to 3h
  [31:29] RX_PSC_A3_15_13 ro — Reserved
  [28] RX_PSC_A3_12 rw — RX signal detect enable extend control
  [27] RX_PSC_A3_11 rw — RX signal detect filter enable
  [26] RX_PSC_A3_10 rw — RX LFPS detect filter enable
  [25] RX_PSC_A3_9 rw — Reserved - spare
  [24] RX_PSC_A3_8 rw — RX signal detect enable
  [23:21] RX_PSC_A3_7_5 rw — Reserved - spare
  [20] RX_PSC_A3_4 rw — RX equalizer engine enable
  [19] RX_PSC_A3_3 rw — RX DFE equalization enable.
  [18] RX_PSC_A3_2 rw — RX PI enable
  [17] RX_PSC_A3_1 rw — RX e path enable (calibration and eye surf only)
  [16] RX_PSC_A3_0 rw — RX enable
  [15:13] RX_PSC_A2_15_13 ro — Reserved
  [12] RX_PSC_A2_12 rw — RX signal detect enable extend control
  [11] RX_PSC_A2_11 rw — RX signal detect filter enable
  [10] RX_PSC_A2_10 rw — RX LFPS detect filter enable
  [9] RX_PSC_A2_9 rw — Reserved - spare
  [8] RX_PSC_A2_8 rw — RX signal detect enable
  [7:5] RX_PSC_A2_7_5 rw — Reserved - spare
  [4] RX_PSC_A2_4 rw — RX equalizer engine enable
  [3] RX_PSC_A2_3 rw — RX DFE equalization enable.
  [2] RX_PSC_A2_2 rw — RX PI enable
  [1] RX_PSC_A2_1 rw — RX e path enable (calibration and eye surf only)
  [0] RX_PSC_A2_0 rw — RX enable
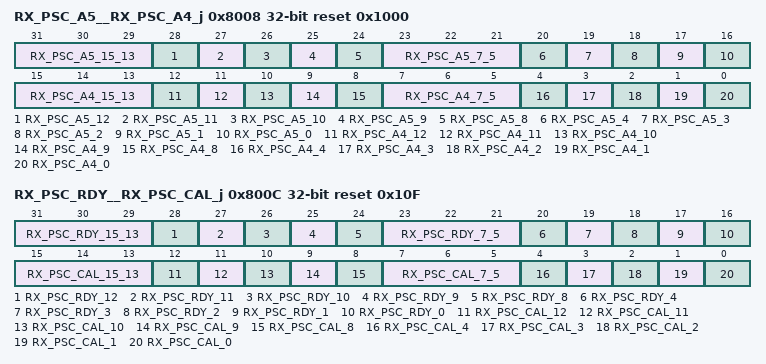
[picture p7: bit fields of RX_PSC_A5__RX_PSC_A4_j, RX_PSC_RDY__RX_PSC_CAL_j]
0x8008 RX_PSC_A5__RX_PSC_A4_j reset 0x1000 — Receiver A4 power state definition register Offset = 8008h + (j * 400h); where j = 0h to 3h
  [31:29] RX_PSC_A5_15_13 ro — Reserved
  [28] RX_PSC_A5_12 rw — RX signal detect enable extend control
  [27] RX_PSC_A5_11 rw — RX signal detect filter enable
  [26] RX_PSC_A5_10 rw — RX LFPS detect filter enable
  [25] RX_PSC_A5_9 rw — Reserved - spare
  [24] RX_PSC_A5_8 rw — RX signal detect enable
  [23:21] RX_PSC_A5_7_5 rw — Reserved - spare
  [20] RX_PSC_A5_4 rw — RX equalizer engine enable
  [19] RX_PSC_A5_3 rw — RX DFE equalization enable.
  [18] RX_PSC_A5_2 rw — RX PI enable
  [17] RX_PSC_A5_1 rw — RX e path enable (calibration and eye surf only)
  [16] RX_PSC_A5_0 rw — RX enable
  [15:13] RX_PSC_A4_15_13 ro — Reserved
  [12] RX_PSC_A4_12 rw — RX signal detect enable extend control
  [11] RX_PSC_A4_11 rw — RX signal detect filter enable
  [10] RX_PSC_A4_10 rw — RX LFPS detect filter enable
  [9] RX_PSC_A4_9 rw — Reserved - spare
  [8] RX_PSC_A4_8 rw — RX signal detect enable
  [7:5] RX_PSC_A4_7_5 rw — Reserved - spare
  [4] RX_PSC_A4_4 rw — RX equalizer engine enable
  [3] RX_PSC_A4_3 rw — RX DFE equalization enable.
  [2] RX_PSC_A4_2 rw — RX PI enable
  [1] RX_PSC_A4_1 rw — RX e path enable (calibration and eye surf only)
  [0] RX_PSC_A4_0 rw — RX enable
0x800C RX_PSC_RDY__RX_PSC_CAL_j reset 0x10F — Receiver calibration power state definition register Offset = 800Ch + (j * 400h); where j = 0h to 3h
  [31:29] RX_PSC_RDY_15_13 ro — Reserved
  [28] RX_PSC_RDY_12 rw — RX signal detect enable extend control
  [27] RX_PSC_RDY_11 rw — RX signal detect filter enable
  [26] RX_PSC_RDY_10 rw — RX LFPS detect filter enable
  [25] RX_PSC_RDY_9 rw — Reserved - spare
  [24] RX_PSC_RDY_8 rw — RX signal detect enable
  [23:21] RX_PSC_RDY_7_5 rw — Reserved - spare
  [20] RX_PSC_RDY_4 rw — RX equalizer engine enable
  [19] RX_PSC_RDY_3 rw — RX DFE equalization enable.
  [18] RX_PSC_RDY_2 rw — RX PI enable
  [17] RX_PSC_RDY_1 rw — RX e path enable (calibration and eye surf only)
  [16] RX_PSC_RDY_0 rw — RX enable
  [15:13] RX_PSC_CAL_15_13 ro — Reserved
  [12] RX_PSC_CAL_12 rw — RX signal detect enable extend control
  [11] RX_PSC_CAL_11 rw — RX signal detect filter enable
  [10] RX_PSC_CAL_10 rw — RX LFPS detect filter enable
  [9] RX_PSC_CAL_9 rw — Reserved - spare
  [8] RX_PSC_CAL_8 rw — RX signal detect enable
  [7:5] RX_PSC_CAL_7_5 rw — Reserved - spare
  [4] RX_PSC_CAL_4 rw — RX equalizer engine enable
  [3] RX_PSC_CAL_3 rw — RX DFE equalization enable.
  [2] RX_PSC_CAL_2 rw — RX PI enable
  [1] RX_PSC_CAL_1 rw — RX e path enable (calibration and eye surf only)
  [0] RX_PSC_CAL_0 rw — RX enable
